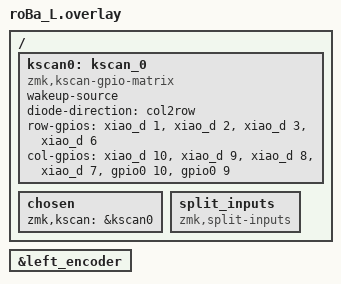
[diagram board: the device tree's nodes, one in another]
#include "roBa.dtsi"

/ {
    kscan0: kscan_0 {
        compatible = "zmk,kscan-gpio-matrix";
        wakeup-source;
        diode-direction = "col2row";
        /* 公式順序 */
        row-gpios
            = <&xiao_d 1 (GPIO_ACTIVE_HIGH | GPIO_PULL_DOWN)>
            , <&xiao_d 2 (GPIO_ACTIVE_HIGH | GPIO_PULL_DOWN)>
            , <&xiao_d 3 (GPIO_ACTIVE_HIGH | GPIO_PULL_DOWN)>
            , <&xiao_d 6 (GPIO_ACTIVE_HIGH | GPIO_PULL_DOWN)>;
        col-gpios
            = <&xiao_d 10 GPIO_ACTIVE_HIGH>
            , <&xiao_d 9 GPIO_ACTIVE_HIGH> 
            , <&xiao_d 8 GPIO_ACTIVE_HIGH> 
            , <&xiao_d 7 GPIO_ACTIVE_HIGH> 
            , <&gpio0 10 GPIO_ACTIVE_HIGH>
            , <&gpio0 9 GPIO_ACTIVE_HIGH>;
    };
    chosen { zmk,kscan = &kscan0; };
    
    /* 左手用のダミー入力定義 (ビルドエラー回避用) */
    split_inputs {
        compatible = "zmk,split-inputs";
        #address-cells = <1>;
        #size-cells = <0>;
        
        /* 中身は空でOK */
    };
};

&left_encoder { status = "okay"; };
